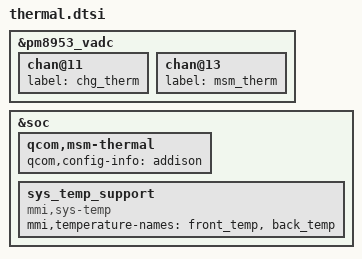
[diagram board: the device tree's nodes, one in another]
&pm8953_vadc {
	chan@11 {
		label = "chg_therm";
	};

	chan@13 {
		label = "msm_therm";
	};
};

&soc {
	qcom,msm-thermal {
		qcom,config-info = "addison";
	};

	sys_temp_support {
		compatible = "mmi,sys-temp";
		mmi,temperature-names = "front_temp",
					"back_temp";
		status = "ok";
	};
};
